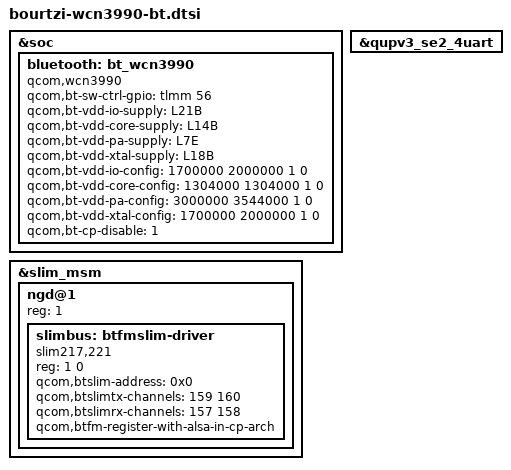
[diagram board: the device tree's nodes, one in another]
// SPDX-License-Identifier: BSD-3-Clause
/*
 * Copyright (c) Qualcomm Technologies, Inc. and/or its subsidiaries.
 */
#include <dt-bindings/interconnect/qcom,ravelin.h>
#include <dt-bindings/interrupt-controller/arm-gic.h>
#include <dt-bindings/gpio/gpio.h>


&soc {
	bluetooth: bt_wcn3990 {
		compatible = "qcom,wcn3990";
		qcom,bt-sw-ctrl-gpio = <&tlmm 56 GPIO_ACTIVE_HIGH>;
		qcom,bt-vdd-io-supply = <&L21B>;  /*WCN3990_1P8_IO*/
		qcom,bt-vdd-core-supply = <&L14B>; /*WCN3990_1P3_RFA*/
		qcom,bt-vdd-pa-supply = <&L7E>; /*WCN3990_3P3_CHAIN0*/
		qcom,bt-vdd-xtal-supply = <&L18B>; /*WCN3990_1P8_XO*/
                
		qcom,bt-vdd-io-config = <1700000 2000000 1 0>;
		qcom,bt-vdd-core-config = <1304000 1304000 1 0>;
		qcom,bt-vdd-pa-config = <3000000 3544000 1 0>;
		qcom,bt-vdd-xtal-config = <1700000 2000000 1 0>;
		qcom,bt-cp-disable = <1>;
	};
};

&slim_msm {
	status =  "ok";
	ngd@1 {
		reg = <1>;
		#address-cells = <1>;
		#size-cells = <1>;
		//slimbus child nodes
		slimbus: btfmslim-driver {
			compatible = "slim217,221";
			reg = <1 0>;
			qcom,btslim-address  = <0x0>;
			qcom,btslimtx-channels = <159 160>;
			qcom,btslimrx-channels = <157 158>;
			qcom,btfm-register-with-alsa-in-cp-arch;
		};
	};
};

//uart instance
&qupv3_se2_4uart {
	status = "ok";
};
